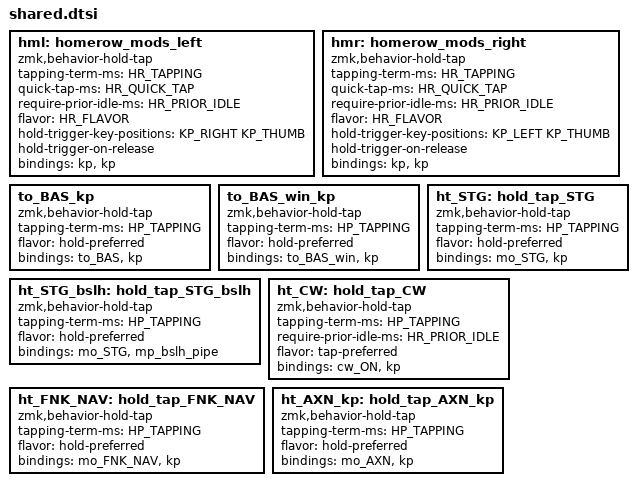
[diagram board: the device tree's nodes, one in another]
// Home-row mods, one behaviour per hand. A hold only registers when the
// next key is on the OTHER hand (or a thumb), so same-hand rolls type
// letters instead of firing modifiers.
//
// require-prior-idle-ms: if a key was pressed within this window the
// hold-tap resolves as a tap immediately, covering normal typing flow.
// Value set by the formula 10500 / WPM (see times.dtsi).
//
// hold-trigger-on-release: defers the positional check to the trigger
// key's release rather than its press. Enables same-hand modifier combos
// (e.g. LGUI+LSHIFT = D+F) that are impossible without it. Costs a small
// delay on same-hand rolls (tap character appears at release not press).
//
// &hml on the left home row (A R S T), &hmr on the right (N E I O).
// Using the wrong one silently disables the positional guard.

hml: homerow_mods_left {
    compatible = "zmk,behavior-hold-tap";
    #binding-cells = <2>;
    tapping-term-ms = <HR_TAPPING>;
    quick-tap-ms = <HR_QUICK_TAP>;
    require-prior-idle-ms = <HR_PRIOR_IDLE>;
    flavor = HR_FLAVOR;
    hold-trigger-key-positions = <KP_RIGHT KP_THUMB>;
    hold-trigger-on-release;
    bindings = <&kp>, <&kp>;
};

hmr: homerow_mods_right {
    compatible = "zmk,behavior-hold-tap";
    #binding-cells = <2>;
    tapping-term-ms = <HR_TAPPING>;
    quick-tap-ms = <HR_QUICK_TAP>;
    require-prior-idle-ms = <HR_PRIOR_IDLE>;
    flavor = HR_FLAVOR;
    hold-trigger-key-positions = <KP_LEFT KP_THUMB>;
    hold-trigger-on-release;
    bindings = <&kp>, <&kp>;
};

// ESC on tap, hard reset to base on hold. The reset is the escape hatch if
// layers ever end up stacked; the MAC variant relights the OS flag that
// &to would otherwise clear.
to_BAS_kp: to_BAS_kp {
    compatible = "zmk,behavior-hold-tap";
    #binding-cells = <2>;
    tapping-term-ms = <HP_TAPPING>;
    flavor = "hold-preferred";
    bindings = <&to_BAS>, <&kp>;
};

to_BAS_win_kp: to_BAS_win_kp {
    compatible = "zmk,behavior-hold-tap";
    #binding-cells = <2>;
    tapping-term-ms = <HP_TAPPING>;
    flavor = "hold-preferred";
    bindings = <&to_BAS_win>, <&kp>;
};

// STG on hold, outer-column key on tap. Two variants:
//   ht_STG       -- generic, tap = &kp, used on TAB (pos 24) for DEL
//   ht_STG_fslh  -- tap = mp_fslh_pipe (/ on tap, | on shift), used on pos 35
// Both halves bound so either hand can hold STG while the other reaches
// a bootloader key. Wrap mo_STG so the host layer signal still fires.
ht_STG: hold_tap_STG {
    compatible = "zmk,behavior-hold-tap";
    #binding-cells = <2>;
    tapping-term-ms = <HP_TAPPING>;
    flavor = "hold-preferred";
    bindings = <&mo_STG>, <&kp>;
};

ht_STG_bslh: hold_tap_STG_bslh {
    compatible = "zmk,behavior-hold-tap";
    #binding-cells = <2>;
    tapping-term-ms = <HP_TAPPING>;
    flavor = "hold-preferred";
    bindings = <&mo_STG>, <&mp_bslh_pipe>;
};

// Caps word on hold, the outer-column key on tap. Used on pos 23, which
// replaces the two caps-word combos (see combos.dtsi for why they went).
//
// tap-preferred is deliberate: ' is an ordinary character and pos 23 is a
// pinky, so only the timer may resolve a hold. Under balanced or
// hold-preferred, rolling out of ' into the other hand would arm caps word.
// Params are dummies in the same style as ht_STG -- cw_ON ignores param1.
// require-prior-idle-ms matters more here than it looks. Pos 23 is ALSO a
// member of the HELP_COMBO on <12 23>, so its output is already withheld
// while that combo is a candidate; tap-preferred then defers the tap to
// key release on top of that. Prior-idle short-circuits both during typing
// flow -- ' emits on press like any other key, and caps word is only
// reachable after a deliberate pause.
ht_CW: hold_tap_CW {
    compatible = "zmk,behavior-hold-tap";
    #binding-cells = <2>;
    tapping-term-ms = <HP_TAPPING>;
    require-prior-idle-ms = <HR_PRIOR_IDLE>;
    flavor = "tap-preferred";
    bindings = <&cw_ON>, <&kp>;
};

// FNK_NAV is accessed from both space thumbs (pos 37 and pos 40).
// Tap sends the key, hold activates the layer momentarily.
// Wraps mo_FNK_NAV rather than a bare &mo so the host signal fires.
ht_FNK_NAV: hold_tap_FNK_NAV {
    compatible = "zmk,behavior-hold-tap";
    #binding-cells = <2>;
    tapping-term-ms = <HP_TAPPING>;
    flavor = "hold-preferred";
    bindings = <&mo_FNK_NAV>, <&kp>;
};

// AXN on hold, key on tap -- same pattern as ht_FNK_NAV.
// Used on pos 38 (left AXN thumb): hold = AXN layer, tap = RET.
ht_AXN_kp: hold_tap_AXN_kp {
    compatible = "zmk,behavior-hold-tap";
    #binding-cells = <2>;
    tapping-term-ms = <HP_TAPPING>;
    flavor = "hold-preferred";
    bindings = <&mo_AXN>, <&kp>;
};

